# STM32F40x register map
File version: 1.5
Registers are 32-bit, read-write, reset 0x0 unless marked. A register's access mark holds for its fields unless they carry their own. Offsets are from the block's base; [hi:lo] are bit positions; {n}, {i} and the like mark numbered series; 'fields as' and 'values as' point back to an identical list.

## OTG_HS_DEVICE（USB_OTG_HS_设备寄存器） — USB OTG HS 设备寄存器（best-effort） | USB on the go high speed
Base 0x40040800
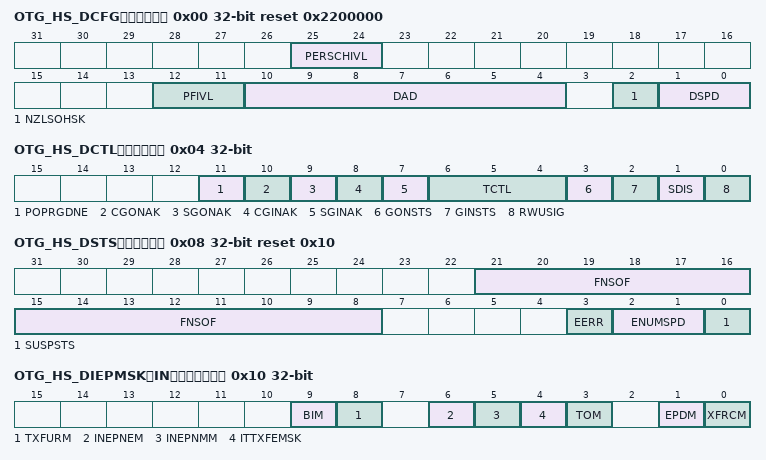
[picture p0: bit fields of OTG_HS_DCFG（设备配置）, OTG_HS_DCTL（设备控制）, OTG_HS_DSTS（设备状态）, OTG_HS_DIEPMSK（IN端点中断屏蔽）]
0x00 OTG_HS_DCFG（设备配置） reset 0x2200000 — 设备配置 | OTG_HS device configuration register
  [25:24] PERSCHIVL — Periodic scheduling interval
  [12:11] PFIVL — Periodic (micro)frame interval
  [10:4] DAD — Device address
  [2] NZLSOHSK — Nonzero-length status OUT handshake
  [1:0] DSPD — Device speed
0x04 OTG_HS_DCTL（设备控制） access per field — 设备控制 | OTG_HS device control register
  [11] POPRGDNE rw — Power-on programming done
  [10] CGONAK wo — Clear global OUT NAK
  [9] SGONAK wo — Set global OUT NAK
  [8] CGINAK wo — Clear global IN NAK
  [7] SGINAK wo — Set global IN NAK
  [6:4] TCTL rw — Test control
  [3] GONSTS ro — Global OUT NAK status
  [2] GINSTS ro — Global IN NAK status
  [1] SDIS rw — Soft disconnect
  [0] RWUSIG rw — Remote wakeup signaling
0x08 OTG_HS_DSTS（设备状态） ro reset 0x10 — 设备状态 | OTG_HS device status register
  [21:8] FNSOF — Frame number of the received SOF
  [3] EERR — Erratic error
  [2:1] ENUMSPD — Enumerated speed
  [0] SUSPSTS — Suspend status
0x10 OTG_HS_DIEPMSK（IN端点中断屏蔽） — IN 端点中断屏蔽 | OTG_HS device IN endpoint common interrupt mask register
  [9] BIM — BNA interrupt mask
  [8] TXFURM — FIFO underrun mask
  [6] INEPNEM — IN endpoint NAK effective mask
  [5] INEPNMM — IN token received with EP mismatch mask
  [4] ITTXFEMSK — IN token received when TxFIFO empty mask
  [3] TOM — Timeout condition mask (nonisochronous endpoints)
  [1] EPDM — Endpoint disabled interrupt mask
  [0] XFRCM — Transfer completed interrupt mask
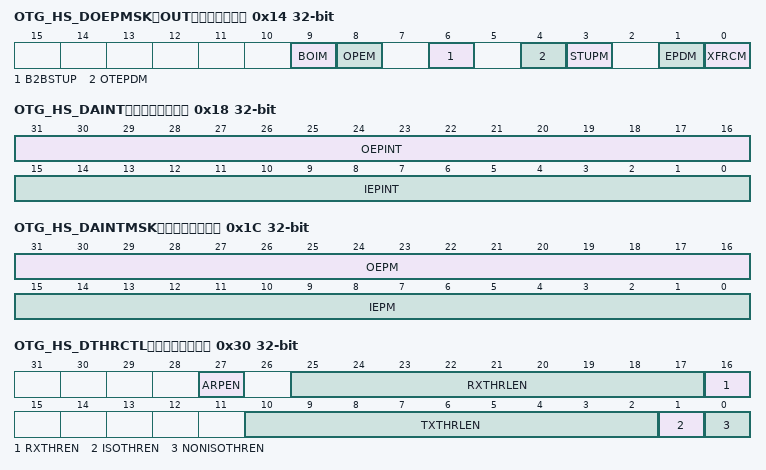
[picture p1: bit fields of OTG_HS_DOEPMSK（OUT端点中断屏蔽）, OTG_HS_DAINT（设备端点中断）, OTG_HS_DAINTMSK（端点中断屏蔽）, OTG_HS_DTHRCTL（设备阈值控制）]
0x14 OTG_HS_DOEPMSK（OUT端点中断屏蔽） — OUT 端点中断屏蔽 | OTG_HS device OUT endpoint common interrupt mask register
  [9] BOIM — BNA interrupt mask
  [8] OPEM — OUT packet error mask
  [6] B2BSTUP — Back-to-back SETUP packets received mask
  [4] OTEPDM — OUT token received when endpoint disabled mask
  [3] STUPM — SETUP phase done mask
  [1] EPDM — Endpoint disabled interrupt mask
  [0] XFRCM — Transfer completed interrupt mask
0x18 OTG_HS_DAINT（设备端点中断） ro — 设备所有端点中断 | OTG_HS device all endpoints interrupt register
  [31:16] OEPINT — OUT endpoint interrupt bits
  [15:0] IEPINT — IN endpoint interrupt bits
0x1C OTG_HS_DAINTMSK（端点中断屏蔽） — 端点中断屏蔽 | OTG_HS all endpoints interrupt mask register
  [31:16] OEPM — OUT EP interrupt mask bits
  [15:0] IEPM — IN EP interrupt mask bits
0x28 OTG_HS_DVBUSDIS（设备VBUS释放） reset 0x17D7 — 设备 VBUS 释放时间 | OTG_HS device VBUS discharge time register
  [15:0] VBUSDT — Device VBUS discharge time
0x2C OTG_HS_DVBUSPULSE（设备VBUS脉冲） reset 0x5B8 — 设备 VBUS 脉冲时间 | OTG_HS device VBUS pulsing time register
  [11:0] DVBUSP — Device VBUS pulsing time
0x30 OTG_HS_DTHRCTL（设备阈值控制） — 设备 FIFO 阈值控制 | OTG_HS Device threshold control register
  [27] ARPEN — Arbiter parking enable
  [25:17] RXTHRLEN — Receive threshold length
  [16] RXTHREN — Receive threshold enable
  [10:2] TXTHRLEN — Transmit threshold length
  [1] ISOTHREN — ISO IN endpoint threshold enable
  [0] NONISOTHREN — Nonisochronous IN endpoints threshold enable
0x34 OTG_HS_DIEPEMPMSK（OTGHS寄存器 DIEPEMPMSK） — USB OTG HS 寄存器 DIEPEMPMSK（best-effort） | OTG_HS device IN endpoint FIFO empty interrupt mask register
  [15:0] INEPTXFEM — IN EP Tx FIFO empty interrupt mask bits
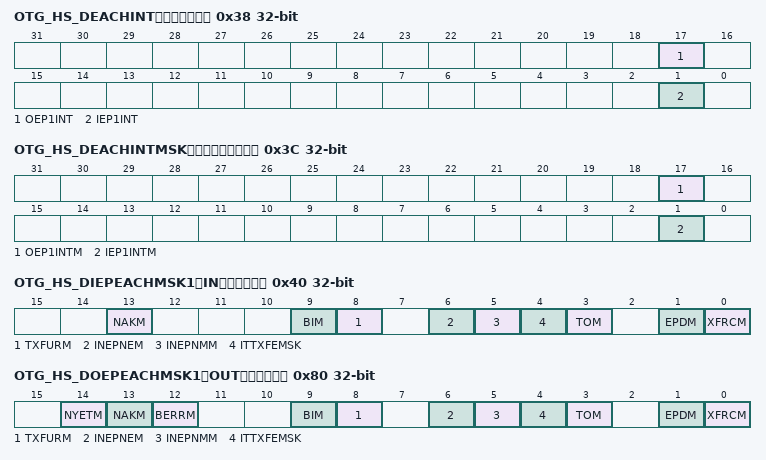
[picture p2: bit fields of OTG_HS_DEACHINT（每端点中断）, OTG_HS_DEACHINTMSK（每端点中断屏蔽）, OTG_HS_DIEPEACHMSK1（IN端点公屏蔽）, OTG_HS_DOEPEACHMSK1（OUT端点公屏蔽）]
0x38 OTG_HS_DEACHINT（每端点中断） — 每端点中断 | OTG_HS device each endpoint interrupt register
  [17] OEP1INT — OUT endpoint 1 interrupt bit
  [1] IEP1INT — IN endpoint 1interrupt bit
0x3C OTG_HS_DEACHINTMSK（每端点中断屏蔽） — 每端点中断屏蔽 | OTG_HS device each endpoint interrupt register mask
  [17] OEP1INTM — OUT Endpoint 1 interrupt mask bit
  [1] IEP1INTM — IN Endpoint 1 interrupt mask bit
0x40 OTG_HS_DIEPEACHMSK1（IN端点公屏蔽） — IN 端点公共中断屏蔽 1 | OTG_HS device each in endpoint-1 interrupt register
  [13] NAKM — NAK interrupt mask
  [9] BIM — BNA interrupt mask
  [8] TXFURM — FIFO underrun mask
  [6] INEPNEM — IN endpoint NAK effective mask
  [5] INEPNMM — IN token received with EP mismatch mask
  [4] ITTXFEMSK — IN token received when TxFIFO empty mask
  [3] TOM — Timeout condition mask (nonisochronous endpoints)
  [1] EPDM — Endpoint disabled interrupt mask
  [0] XFRCM — Transfer completed interrupt mask
0x80 OTG_HS_DOEPEACHMSK1（OUT端点公屏蔽） — OUT 端点公共中断屏蔽 1 | OTG_HS device each OUT endpoint-1 interrupt register
  [14] NYETM — NYET interrupt mask
  [13] NAKM — NAK interrupt mask
  [12] BERRM — Bubble error interrupt mask
  [9] BIM — BNA interrupt mask
  [8] TXFURM — OUT packet error mask
  [6] INEPNEM — IN endpoint NAK effective mask
  [5] INEPNMM — IN token received with EP mismatch mask
  [4] ITTXFEMSK — IN token received when TxFIFO empty mask
  [3] TOM — Timeout condition mask
  [1] EPDM — Endpoint disabled interrupt mask
  [0] XFRCM — Transfer completed interrupt mask
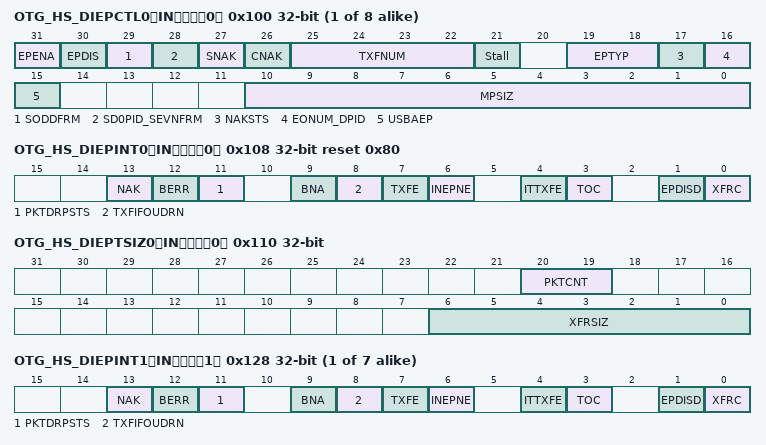
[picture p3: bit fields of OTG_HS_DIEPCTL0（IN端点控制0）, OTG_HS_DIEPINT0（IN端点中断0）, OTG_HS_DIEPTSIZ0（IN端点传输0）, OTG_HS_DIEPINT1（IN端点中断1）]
{0x100+0x20*i} OTG_HS_DIEPCTL{i}（IN端点控制{i}） access per field (i=0..7) — USB OTG HS IN端点控制{i} | OTG device endpoint-{i} control register
  [31] EPENA rw — Endpoint enable
  [30] EPDIS rw — Endpoint disable
  [29] SODDFRM wo — Set odd frame
  [28] SD0PID_SEVNFRM wo — Set DATA0 PID
  [27] SNAK wo — Set NAK
  [26] CNAK wo — Clear NAK
  [25:22] TXFNUM rw — TxFIFO number
  [21] Stall rw — STALL handshake
  [19:18] EPTYP rw — Endpoint type
  [17] NAKSTS ro — NAK status
  [16] EONUM_DPID ro — Even/odd frame
  [15] USBAEP rw — USB active endpoint
  [10:0] MPSIZ rw — Maximum packet size
0x108 OTG_HS_DIEPINT0（IN端点中断0） access per field reset 0x80 — USB OTG HS IN端点中断0 | OTG device endpoint-0 interrupt register
  [13] NAK rw — NAK interrupt
  [12] BERR rw — Babble error interrupt
  [11] PKTDRPSTS rw — Packet dropped status
  [9] BNA rw — Buffer not available interrupt
  [8] TXFIFOUDRN rw — Transmit Fifo Underrun
  [7] TXFE ro — Transmit FIFO empty
  [6] INEPNE rw — IN endpoint NAK effective
  [4] ITTXFE rw — IN token received when TxFIFO is empty
  [3] TOC rw — Timeout condition
  [1] EPDISD rw — Endpoint disabled interrupt
  [0] XFRC rw — Transfer completed interrupt
0x110 OTG_HS_DIEPTSIZ0（IN端点传输0） — USB OTG HS IN端点传输0 | OTG_HS device IN endpoint 0 transfer size register
  [20:19] PKTCNT — Packet count
  [6:0] XFRSIZ — Transfer size
{0xF4+0x20*i} OTG_HS_DIEPDMA{i}（IN端点DMA{i}） (i=1..5) — USB OTG HS IN端点DMA{i} | OTG_HS device endpoint-{i} DMA address register
  [31:0] DMAADDR — DMA address
{0x118+0x20*i} OTG_HS_DTXFSTS{i}（OTGHS寄存器 DTXFSTS{i}） ro (i=0..5) — USB OTG HS 寄存器 DTXFSTS{i}（best-effort） | OTG_HS device IN endpoint transmit FIFO status register
  [15:0] INEPTFSAV — IN endpoint TxFIFO space avail
{0x108+0x20*i} OTG_HS_DIEPINT{i}（IN端点中断{i}） access per field (i=1..7) — USB OTG HS IN端点中断{i} | OTG device endpoint-{i} interrupt register
  fields as OTG_HS_DIEPINT0（IN端点中断0）
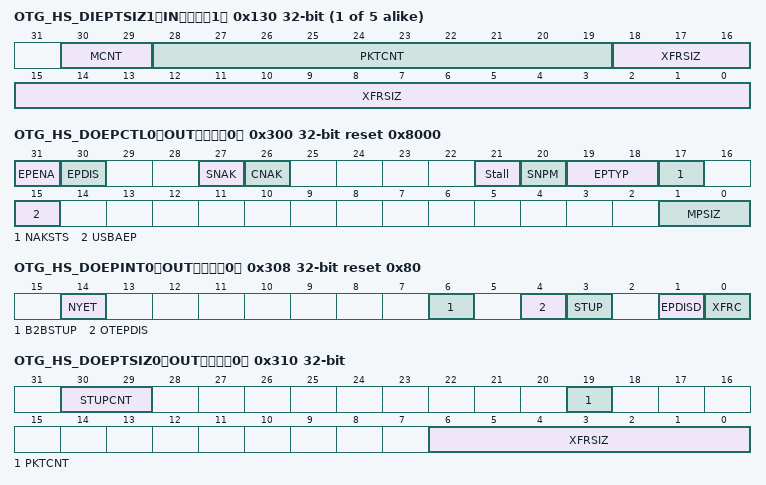
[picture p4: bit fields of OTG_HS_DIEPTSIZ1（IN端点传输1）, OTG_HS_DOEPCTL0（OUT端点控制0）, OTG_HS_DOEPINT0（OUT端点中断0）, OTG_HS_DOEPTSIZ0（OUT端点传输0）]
{0x110+0x20*i} OTG_HS_DIEPTSIZ{i}（IN端点传输{i}） (i=1..5) — USB OTG HS IN端点传输{i} | OTG_HS device endpoint transfer size register
  [30:29] MCNT — Multi count
  [28:19] PKTCNT — Packet count
  [18:0] XFRSIZ — Transfer size
0x300 OTG_HS_DOEPCTL0（OUT端点控制0） access per field reset 0x8000 — USB OTG HS OUT端点控制0 | OTG_HS device control OUT endpoint 0 control register
  [31] EPENA wo — Endpoint enable
  [30] EPDIS ro — Endpoint disable
  [27] SNAK wo — Set NAK
  [26] CNAK wo — Clear NAK
  [21] Stall rw — STALL handshake
  [20] SNPM rw — Snoop mode
  [19:18] EPTYP ro — Endpoint type
  [17] NAKSTS ro — NAK status
  [15] USBAEP ro — USB active endpoint
  [1:0] MPSIZ ro — Maximum packet size
0x308 OTG_HS_DOEPINT0（OUT端点中断0） reset 0x80 — USB OTG HS OUT端点中断0 | OTG_HS device endpoint-0 interrupt register
  [14] NYET — NYET interrupt
  [6] B2BSTUP — Back-to-back SETUP packets received
  [4] OTEPDIS — OUT token received when endpoint disabled
  [3] STUP — SETUP phase done
  [1] EPDISD — Endpoint disabled interrupt
  [0] XFRC — Transfer completed interrupt
0x310 OTG_HS_DOEPTSIZ0（OUT端点传输0） — USB OTG HS OUT端点传输0 | OTG_HS device endpoint-1 transfer size register
  [30:29] STUPCNT — SETUP packet count
  [19] PKTCNT — Packet count
  [6:0] XFRSIZ — Transfer size
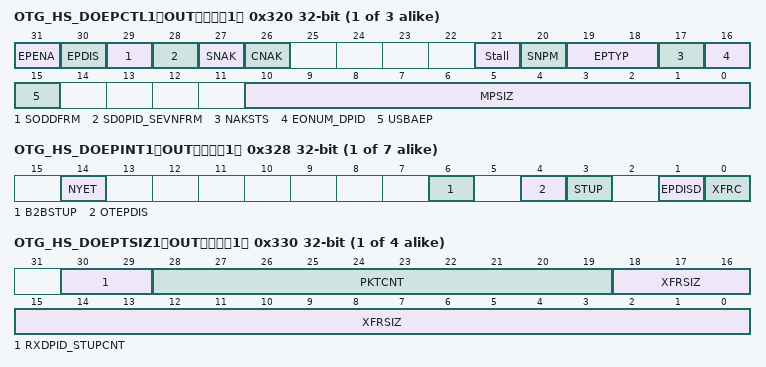
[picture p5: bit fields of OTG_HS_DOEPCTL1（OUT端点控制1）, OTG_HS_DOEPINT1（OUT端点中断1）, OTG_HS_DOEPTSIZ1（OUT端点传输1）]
{0x300+0x20*i} OTG_HS_DOEPCTL{i}（OUT端点控制{i}） access per field (i=1..3) — USB OTG HS OUT端点控制{i} | OTG device endpoint-{i} control register
  [31] EPENA rw — Endpoint enable
  [30] EPDIS rw — Endpoint disable
  [29] SODDFRM wo — Set odd frame
  [28] SD0PID_SEVNFRM wo — Set DATA0 PID/Set even frame
  [27] SNAK wo — Set NAK
  [26] CNAK wo — Clear NAK
  [21] Stall rw — STALL handshake
  [20] SNPM rw — Snoop mode
  [19:18] EPTYP rw — Endpoint type
  [17] NAKSTS ro — NAK status
  [16] EONUM_DPID ro — Even odd frame/Endpoint data PID
  [15] USBAEP rw — USB active endpoint
  [10:0] MPSIZ rw — Maximum packet size
{0x308+0x20*i} OTG_HS_DOEPINT{i}（OUT端点中断{i}） (i=1..7) — USB OTG HS OUT端点中断{i} | OTG_HS device endpoint-{i} interrupt register
  fields as OTG_HS_DOEPINT0（OUT端点中断0）
{0x310+0x20*i} OTG_HS_DOEPTSIZ{i}（OUT端点传输{i}） (i=1..4) — USB OTG HS OUT端点传输{i} | OTG_HS device endpoint-{i+1} transfer size register
  [30:29] RXDPID_STUPCNT — Received data PID/SETUP packet count
  [28:19] PKTCNT — Packet count
  [18:0] XFRSIZ — Transfer size
